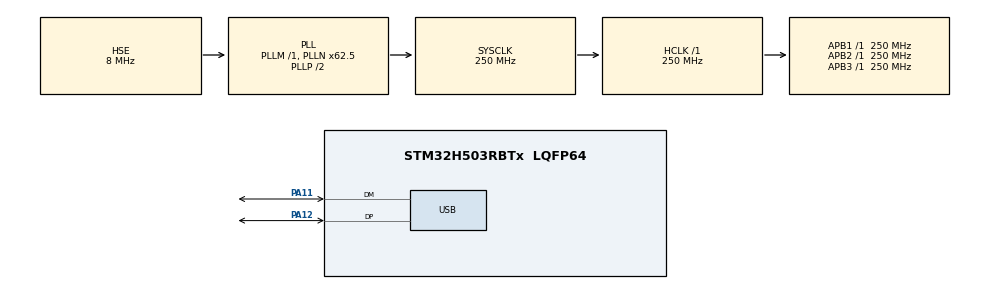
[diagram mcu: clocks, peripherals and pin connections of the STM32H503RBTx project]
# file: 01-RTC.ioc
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CORTEX_M33_NS.Number-Cortex_Memory_Protection_Unit_Region0_OTP_RO_AREAS_Settings=MPU_REGION_NUMBER0
CORTEX_M33_NS.default_mode_Activation=1
Mcu.Family=STM32H5
Mcu.Name=STM32H503RBTx
Mcu.Package=LQFP64
NVIC.PriorityGroup=NVIC_PRIORITYGROUP_4
NVIC.USB_DRD_FS_IRQn=true\:0\:0\:false\:false\:true\:true\:true\:true
PA11.Mode=Device
PA11.Signal=USB_DM
PA12.Mode=Device
PA12.Signal=USB_DP
PA13(JTMS/SWDIO).Mode=Serial_Wire
PA13(JTMS/SWDIO).Signal=DEBUG_JTMS-SWDIO
PA14(JTCK/SWCLK).Mode=Serial_Wire
PA14(JTCK/SWCLK).Signal=DEBUG_JTCK-SWCLK
PC14-OSC32_IN(OSC32_IN).Mode=LSE-External-Oscillator
PC14-OSC32_IN(OSC32_IN).Signal=RCC_OSC32_IN
PC15-OSC32_OUT(OSC32_OUT).Mode=LSE-External-Oscillator
PC15-OSC32_OUT(OSC32_OUT).Signal=RCC_OSC32_OUT
PH0-OSC_IN(PH0).Mode=HSE-External-Oscillator
PH0-OSC_IN(PH0).Signal=RCC_OSC_IN
PH1-OSC_OUT(PH1).Mode=HSE-External-Oscillator
PH1-OSC_OUT(PH1).Signal=RCC_OSC_OUT
ProjectManager.HeapSize=0x200
ProjectManager.StackSize=0x2000
ProjectManager.TargetToolchain=MDK-ARM V5.37
RCC.ADCFreq_Value=250000000
RCC.AHBFreq_Value=250000000
RCC.APB1Freq_Value=250000000
RCC.APB1TimFreq_Value=250000000
RCC.APB2Freq_Value=250000000
RCC.APB2TimFreq_Value=250000000
RCC.APB3Freq_Value=250000000
RCC.CSI_VALUE=4000000
RCC.CortexFreq_Value=250000000
RCC.EPOD_VALUE=8000000
RCC.HCLKFreq_Value=250000000
RCC.HSE_VALUE=8000000
RCC.HSI48_VALUE=48000000
RCC.HSI_VALUE=64000000
RCC.LSE_Drive_Capability=RCC_LSEDRIVE_MEDIUMHIGH
RCC.LSIRC_VALUE=32000
RCC.PLLFRACN=4096
RCC.PLLN=62
RCC.PLLSourceVirtual=RCC_PLL1_SOURCE_HSE
RCC.RTCClockSelection=RCC_RTCCLKSOURCE_LSE
RCC.SYSCLKFreq_VALUE=250000000
RCC.SYSCLKSource=RCC_SYSCLKSOURCE_PLLCLK
RCC.USBFreq_Value=48000000
RCC.VCOOutputFreq_Value=500000000
RTC.Year=26
USB.VirtualMode=Device_Only
USBX.BSP.number=1
USBX.Core_System=1
USBX.REG_USBX_DEVICE_CON_CK=0
USBX.USBD_CDCACM_EPIN_ADDR=2
USBX.USBD_CDCACM_EPOUT_ADDR=3
USBX.USBX_SYS_SIZE=1024*4
USBX.UX_APP_MEM_POOL_SIZE_STANDALONE=8192
USBX.UX_DEVICE_CDC_ACM=1
USBX.UX_DEVICE_CLASS_CDC_ACM_WRITE_AUTO_ZLP=1
USBX.UX_DEVICE_ENABLED_FS=1
USBX.UX_Device_Controller=1
USBX.UX_Device_CoreStack=1
USBX.UX_SLAVE_REQUEST_DATA_MAX_LENGTH=512
USBX.UX_enabled_FS=1
USBX0.BSP.STBoard=false
USBX0.BSP.api=Unknown
USBX0.BSP.condition=\!DIE47A
USBX0.BSP.instance=USB
USBX0.BSP.ip=USB
USBX0.BSP.mode=Device_Only
USBX0.BSP.name=USB_Device
USBX0.BSP.solution=USB
VP_BOOTPATH_VS_BOOTPATH.Mode=BP_Activate
VP_CORTEX_M33_NS_VS_Hclk.Mode=Hclk_Mode
VP_ICACHE_VS_ICACHE.Mode=DirectMappedCache
VP_MEMORYMAP_VS_MEMORYMAP.Mode=CurAppReg
VP_PWR_VS_LPOM.Mode=PowerOptimisation
VP_PWR_VS_SECSignals.Mode=Security/Privilege
VP_RTC_VS_RTC_Activate.Mode=RTC_Enabled
VP_RTC_VS_RTC_Calendar.Mode=RTC_Calendar
VP_USBX_Core_System.Mode=Core_System
VP_USBX_UX\ Device\ CDC\ ACM\ Class_FS.Mode=UX_Device_class_CDC_ACM_FS_HS
VP_USBX_UX\ Device\ Controller_FS.Mode=UX_Device_Controller_FS
VP_USBX_UX\ Device\ CoreStack_FS.Mode=UX_Device_CoreStack
board=custom

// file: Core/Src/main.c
/* USER CODE BEGIN Header */
/**
  ******************************************************************************
  * @file           : main.c
  * @brief          : Main program body
  ******************************************************************************
  * @attention
  *
  * Copyright (c) 2026 STMicroelectronics.
  * All rights reserved.
  *
  * This software is licensed under terms that can be found in the LICENSE file
  * in the root directory of this software component.
  * If no LICENSE file comes with this software, it is provided AS-IS.
  *
  ******************************************************************************
  */
/* USER CODE END Header */
#include "main.h"
#include "icache.h"
#include "rtc.h"
#include "usb.h"
#include "app_usbx.h"
#include "gpio.h"

/* USER CODE BEGIN Includes */
#include "board.h"
/* USER CODE END Includes */

void SystemClock_Config(void);
static void MPU_Config(void);

int main(void)
{

  /* MCU Configuration--------------------------------------------------------*/

  /* MPU Configuration--------------------------------------------------------*/
  MPU_Config();

  /* Reset of all peripherals, Initializes the Flash interface and the Systick. */
  HAL_Init();

  /* Configure the system clock */
  SystemClock_Config();

  /* Initialize all configured peripherals */
  MX_GPIO_Init();
  MX_ICACHE_Init();
  MX_RTC_Init();
  MX_USBX_Init();
  /* USER CODE BEGIN 2 */
  HAL_PCD_Start(&hpcd_USB_DRD_FS);

  board_led_init();
	board_button_init();

  uint32_t tick = HAL_GetTick();
	uint32_t tick_usb_tx = tick;
	uint32_t tick_button = tick;

	uint8_t txbuf[50];
	ULONG length;
	ULONG actual_length;
	length = sprintf(( char *)txbuf,"Hello! WeAct Studio\r\n");
	UINT write_state = UX_STATE_RESET;
	UINT ux_status = UX_STATE_RESET;

  /* USER CODE END 2 */

  /* Infinite loop */
  /* USER CODE BEGIN WHILE */
  while (1)
  {
    ux_device_stack_tasks_run();

    tick = HAL_GetTick();
    if(tick >= tick_button)
		{
			if(board_button_getstate())
			{
				tick_button = tick + 100;
				board_led_toggle();
				length = sprintf(( char *)txbuf,"Key Pressed\r\n");
			}
			else
			{
				tick_button = tick + 500;
				RTC_DateTypeDef sdatestructureget;
        RTC_TimeTypeDef stimestructureget;
        static uint8_t Seconds_o;
        int text_lenth;

        /* Get the RTC current Time */
        HAL_RTC_GetTime(&hrtc, &stimestructureget, RTC_FORMAT_BIN);
        /* Get the RTC current Date */
        HAL_RTC_GetDate(&hrtc, &sdatestructureget, RTC_FORMAT_BIN);

        if(Seconds_o != stimestructureget.Seconds)
        {
          Seconds_o = stimestructureget.Seconds;

          board_led_set(1);

          length = sprintf((char *) &txbuf,"20%02d.%02d.%02d %02d:%02d %02d\r\n",sdatestructureget.Year,sdatestructureget.Month,sdatestructureget.Date, \
                                            stimestructureget.Hours,stimestructureget.Minutes,stimestructureget.Seconds);
        }
        else
        {
          board_led_set(0);
        }
			}
		}

		if(tick >= tick_usb_tx)
		{
			tick_usb_tx = tick + 1;

			extern UX_SLAVE_CLASS_CDC_ACM  *cdc_acm;
			if(cdc_acm != UX_NULL)
			{
				switch(write_state)
				{
				case UX_STATE_RESET:

					ux_status = ux_device_class_cdc_acm_write_run(cdc_acm, txbuf,length, &actual_length);

					if (ux_status != UX_STATE_WAIT)
					{
						/* Reset state.  */
						write_state = UX_STATE_RESET;
						break;
					}
					write_state = UX_STATE_WAIT;
					break;

				case UX_STATE_WAIT:
					/* Continue to run state machine.  */
					ux_status = ux_device_class_cdc_acm_write_run(cdc_acm, UX_NULL, 0, &actual_length);
					/* Check if there is  fatal error.  */
					if (ux_status < UX_STATE_IDLE)
					{
						/* Reset state.  */
						write_state = UX_STATE_RESET;
						break;
					}
					/* Check if dataset is transmitted */
					if (ux_status <= UX_STATE_NEXT)
					{
						write_state = UX_STATE_RESET;
						tick_usb_tx = tick + 1000;
					}
					/* Keep waiting.  */
					break;
				default:
					break;
				}
			}
		}
    /* USER CODE END WHILE */

  }
}

void SystemClock_Config(void)
{
  RCC_OscInitTypeDef RCC_OscInitStruct = {0};
  RCC_ClkInitTypeDef RCC_ClkInitStruct = {0};

  /** Configure the main internal regulator output voltage
  */
  __HAL_PWR_VOLTAGESCALING_CONFIG(PWR_REGULATOR_VOLTAGE_SCALE0);

  while(!__HAL_PWR_GET_FLAG(PWR_FLAG_VOSRDY)) {}

  /** Configure LSE Drive Capability
  *  Warning : Only applied when the LSE is disabled.
  */
  HAL_PWR_EnableBkUpAccess();
  __HAL_RCC_LSEDRIVE_CONFIG(RCC_LSEDRIVE_MEDIUMHIGH);

  /** Initializes the RCC Oscillators according to the specified parameters
  * in the RCC_OscInitTypeDef structure.
  */
  RCC_OscInitStruct.OscillatorType = RCC_OSCILLATORTYPE_HSI48|RCC_OSCILLATORTYPE_HSE
                              |RCC_OSCILLATORTYPE_LSE;
  RCC_OscInitStruct.HSEState = RCC_HSE_ON;
  RCC_OscInitStruct.LSEState = RCC_LSE_ON;
  RCC_OscInitStruct.HSI48State = RCC_HSI48_ON;
  RCC_OscInitStruct.PLL.PLLState = RCC_PLL_ON;
  RCC_OscInitStruct.PLL.PLLSource = RCC_PLL1_SOURCE_HSE;
  RCC_OscInitStruct.PLL.PLLM = 1;
  RCC_OscInitStruct.PLL.PLLN = 62;
  RCC_OscInitStruct.PLL.PLLP = 2;
  RCC_OscInitStruct.PLL.PLLQ = 2;
  RCC_OscInitStruct.PLL.PLLR = 2;
  RCC_OscInitStruct.PLL.PLLRGE = RCC_PLL1_VCIRANGE_3;
  RCC_OscInitStruct.PLL.PLLVCOSEL = RCC_PLL1_VCORANGE_WIDE;
  RCC_OscInitStruct.PLL.PLLFRACN = 4096;
  if (HAL_RCC_OscConfig(&RCC_OscInitStruct) != HAL_OK)
  {
    Error_Handler();
  }

  /** Initializes the CPU, AHB and APB buses clocks
  */
  RCC_ClkInitStruct.ClockType = RCC_CLOCKTYPE_HCLK|RCC_CLOCKTYPE_SYSCLK
                              |RCC_CLOCKTYPE_PCLK1|RCC_CLOCKTYPE_PCLK2
                              |RCC_CLOCKTYPE_PCLK3;
  RCC_ClkInitStruct.SYSCLKSource = RCC_SYSCLKSOURCE_PLLCLK;
  RCC_ClkInitStruct.AHBCLKDivider = RCC_SYSCLK_DIV1;
  RCC_ClkInitStruct.APB1CLKDivider = RCC_HCLK_DIV1;
  RCC_ClkInitStruct.APB2CLKDivider = RCC_HCLK_DIV1;
  RCC_ClkInitStruct.APB3CLKDivider = RCC_HCLK_DIV1;

  if (HAL_RCC_ClockConfig(&RCC_ClkInitStruct, FLASH_LATENCY_5) != HAL_OK)
  {
    Error_Handler();
  }

  /** Configure the programming delay
  */
  __HAL_FLASH_SET_PROGRAM_DELAY(FLASH_PROGRAMMING_DELAY_2);
}

 /* MPU Configuration */

void MPU_Config(void)
{
  MPU_Region_InitTypeDef MPU_InitStruct = {0};
  MPU_Attributes_InitTypeDef MPU_AttributesInit = {0};

  /* Disables the MPU */
  HAL_MPU_Disable();

  /** Initializes and configures the Region 0 and the memory to be protected
  */
  MPU_InitStruct.Enable = MPU_REGION_ENABLE;
  MPU_InitStruct.Number = MPU_REGION_NUMBER0;
  MPU_InitStruct.BaseAddress = 0x08FFF000;
  MPU_InitStruct.LimitAddress = 0x08FFFFFF;
  MPU_InitStruct.AttributesIndex = MPU_ATTRIBUTES_NUMBER0;
  MPU_InitStruct.AccessPermission = MPU_REGION_ALL_RO;
  MPU_InitStruct.DisableExec = MPU_INSTRUCTION_ACCESS_DISABLE;
  MPU_InitStruct.IsShareable = MPU_ACCESS_NOT_SHAREABLE;

  HAL_MPU_ConfigRegion(&MPU_InitStruct);

  /** Initializes and configures the Attribute 0 and the memory to be protected
  */
  MPU_AttributesInit.Number = MPU_ATTRIBUTES_NUMBER0;
  MPU_AttributesInit.Attributes = INNER_OUTER(MPU_NOT_CACHEABLE);

  HAL_MPU_ConfigMemoryAttributes(&MPU_AttributesInit);
  /* Enables the MPU */
  HAL_MPU_Enable(MPU_PRIVILEGED_DEFAULT);

}

void Error_Handler(void)
{
  __disable_irq();
  while (1)
  {
  }
}
